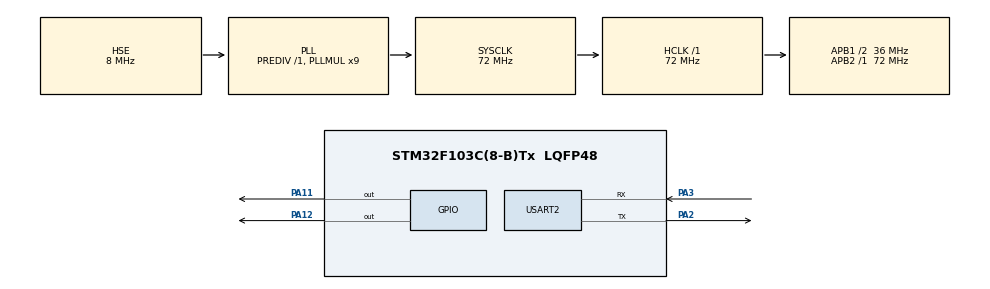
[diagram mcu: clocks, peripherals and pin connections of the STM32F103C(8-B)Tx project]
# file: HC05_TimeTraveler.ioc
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Mcu.Family=STM32F1
Mcu.Name=STM32F103C(8-B)Tx
Mcu.Package=LQFP48
NVIC.PriorityGroup=NVIC_PRIORITYGROUP_4
PA11.Signal=GPIO_Output
PA12.Signal=GPIO_Output
PA2.Mode=Asynchronous
PA2.Signal=USART2_TX
PA3.Mode=Asynchronous
PA3.Signal=USART2_RX
PD0-OSC_IN.Mode=HSE-External-Oscillator
PD0-OSC_IN.Signal=RCC_OSC_IN
PD1-OSC_OUT.Mode=HSE-External-Oscillator
PD1-OSC_OUT.Signal=RCC_OSC_OUT
ProjectManager.HeapSize=0x200
ProjectManager.StackSize=0x400
ProjectManager.TargetToolchain=STM32CubeIDE
RCC.AHBFreq_Value=72000000
RCC.APB1CLKDivider=RCC_HCLK_DIV2
RCC.APB1Freq_Value=36000000
RCC.APB1TimFreq_Value=72000000
RCC.APB2Freq_Value=72000000
RCC.APB2TimFreq_Value=72000000
RCC.HCLKFreq_Value=72000000
RCC.PLLMUL=RCC_PLL_MUL9
RCC.PLLSourceVirtual=RCC_PLLSOURCE_HSE
RCC.SYSCLKFreq_VALUE=72000000
RCC.SYSCLKSource=RCC_SYSCLKSOURCE_PLLCLK
RCC.USBFreq_Value=72000000
RTC.Date=14
RTC.Month=RTC_MONTH_NOVEMBER
RTC.Year=22
USART2.VirtualMode=VM_ASYNC
VP_RTC_VS_RTC_Activate.Mode=RTC_Enabled
VP_RTC_VS_RTC_Calendar.Mode=RTC_Calendar
board=custom

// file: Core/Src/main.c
/* USER CODE BEGIN Header */
/**
  ******************************************************************************
  * @file           : main.c
  * @brief          : Main program body
  ******************************************************************************
  * @attention
  *
  * Copyright (c) 2022 STMicroelectronics.
  * All rights reserved.
  *
  * This software is licensed under terms that can be found in the LICENSE file
  * in the root directory of this software component.
  * If no LICENSE file comes with this software, it is provided AS-IS.
  *
  ******************************************************************************
  */
/* USER CODE END Header */
#include "main.h"
#include <string.h>

RTC_HandleTypeDef hrtc;

UART_HandleTypeDef huart2;

void SystemClock_Config(void);
static void MX_GPIO_Init(void);
static void MX_RTC_Init(void);
static void MX_USART2_UART_Init(void);
void get_time(void);

int main(void)
{

  /* MCU Configuration--------------------------------------------------------*/

  /* Reset of all peripherals, Initializes the Flash interface and the Systick. */
  HAL_Init();

  /* Configure the system clock */
  SystemClock_Config();

  /* Initialize all configured peripherals */
  MX_GPIO_Init();
  MX_RTC_Init();//hay que ponerlo afuera del main ?NO.
  MX_USART2_UART_Init();

  /* Infinite loop */
  /* USER CODE BEGIN WHILE */
  char data_in[1];
  char msg0[]="\nHC-05 Bluetooth with STM32\n";
  char msg1[]="\nHola, la temperatura es: 27°C\n";
  char msg2[]="\nAT-COMMANDS\n";
  int32_t before = RTC_BKP_DR1;
  int32_t after = 0;
  int counterA=0;
  int counterB=0;
  char tramaA[60];
  char tramaB[60];
   //serapp
  HAL_UART_Transmit(&huart2, (uint8_t*) msg0, strlen(msg0), HAL_MAX_DELAY);
  while (1)
  {
     /* USER CODE END WHILE */
 	  HAL_UART_Receive(&huart2, (uint8_t*)data_in, 1, HAL_MAX_DELAY);
 	  //hacerlo pero con interrupts cosa que el counter
	  //cuente bien y no espere a recibir algo para actuar
 	  if(RTC_BKP_DR1 == before){
 		  counterA++;
 	  }else{
 		  counterB++;
 	  }
 	  before=RTC_BKP_DR1;

 	  if(data_in[0]=='1'){//hora
 		  HAL_GPIO_WritePin(GPIOA, GPIO_PIN_11, GPIO_PIN_RESET);
 		  //HAL_UART_Transmit(&huart2, (uint8_t*) msg2, strlen(msg2), HAL_MAX_DELAY);
 		  get_time();
 	  } else if (data_in[0]=='2'){//temperatura
 		  HAL_GPIO_WritePin(GPIOA, GPIO_PIN_11, GPIO_PIN_SET);
 		  sprintf(tramaA, "%hu A\n", counterA);
 		  sprintf(tramaB, "%hu B\n", counterB);
 		  strcat(tramaA,tramaB);
 		  strcat(msg1,tramaA);
 		  HAL_UART_Transmit(&huart2, (uint8_t*) msg1, strlen(msg1), HAL_MAX_DELAY);
 	  }
 	  else if (data_in[0]=='3') {//at
 		 HAL_UART_Transmit(&huart2, (uint8_t*) msg2, strlen(msg2), HAL_MAX_DELAY);
 	  }
   }
}

void SystemClock_Config(void)
{
  RCC_OscInitTypeDef RCC_OscInitStruct = {0};
  RCC_ClkInitTypeDef RCC_ClkInitStruct = {0};
  RCC_PeriphCLKInitTypeDef PeriphClkInit = {0};

  /** Initializes the RCC Oscillators according to the specified parameters
  * in the RCC_OscInitTypeDef structure.
  */
  RCC_OscInitStruct.OscillatorType = RCC_OSCILLATORTYPE_LSI|RCC_OSCILLATORTYPE_HSE;
  RCC_OscInitStruct.HSEState = RCC_HSE_ON;
  RCC_OscInitStruct.HSEPredivValue = RCC_HSE_PREDIV_DIV1;
  RCC_OscInitStruct.HSIState = RCC_HSI_ON;
  RCC_OscInitStruct.LSIState = RCC_LSI_ON;
  RCC_OscInitStruct.PLL.PLLState = RCC_PLL_ON;
  RCC_OscInitStruct.PLL.PLLSource = RCC_PLLSOURCE_HSE;
  RCC_OscInitStruct.PLL.PLLMUL = RCC_PLL_MUL9;
  if (HAL_RCC_OscConfig(&RCC_OscInitStruct) != HAL_OK)
  {
    Error_Handler();
  }

  /** Initializes the CPU, AHB and APB buses clocks
  */
  RCC_ClkInitStruct.ClockType = RCC_CLOCKTYPE_HCLK|RCC_CLOCKTYPE_SYSCLK
                              |RCC_CLOCKTYPE_PCLK1|RCC_CLOCKTYPE_PCLK2;
  RCC_ClkInitStruct.SYSCLKSource = RCC_SYSCLKSOURCE_PLLCLK;
  RCC_ClkInitStruct.AHBCLKDivider = RCC_SYSCLK_DIV1;
  RCC_ClkInitStruct.APB1CLKDivider = RCC_HCLK_DIV2;
  RCC_ClkInitStruct.APB2CLKDivider = RCC_HCLK_DIV1;

  if (HAL_RCC_ClockConfig(&RCC_ClkInitStruct, FLASH_LATENCY_2) != HAL_OK)
  {
    Error_Handler();
  }
  PeriphClkInit.PeriphClockSelection = RCC_PERIPHCLK_RTC;
  PeriphClkInit.RTCClockSelection = RCC_RTCCLKSOURCE_LSI;
  if (HAL_RCCEx_PeriphCLKConfig(&PeriphClkInit) != HAL_OK)
  {
    Error_Handler();
  }
}

static void MX_RTC_Init(void) //si la uso esta setea el time y un par de cosas más
{

  RTC_TimeTypeDef sTime = {0};
  RTC_DateTypeDef DateToUpdate = {0};

  /** Initialize RTC Only
  */
  hrtc.Instance = RTC;
  hrtc.Init.AsynchPrediv = RTC_AUTO_1_SECOND;
  hrtc.Init.OutPut = RTC_OUTPUTSOURCE_ALARM;
  if (HAL_RTC_Init(&hrtc) != HAL_OK)
  {
    Error_Handler();
  }

  /* USER CODE BEGIN Check_RTC_BKUP */ //no se si va así, si va así
  if(HAL_RTCEx_BKUPRead(&hrtc, RTC_BKP_DR1) == 0x32F2) {
	  //Time is OK. Set Alarms later.
	  //printf("RTC backup available\n");
	  	return;
  }
  //hacer un contador en un registro de back up que se incremente
  //cada vez que pase un segundo de tiempo del otro registro donde se guarda
  //la hora. Esto para saber cuanto tarda en guardar.
  /* USER CODE END Check_RTC_BKUP */

  /** Initialize RTC and set the Time and Date
  */
  sTime.Hours = 0x0;
  sTime.Minutes = 0x0;
  sTime.Seconds = 0x0;

  if (HAL_RTC_SetTime(&hrtc, &sTime, RTC_FORMAT_BCD) != HAL_OK)
  {
    Error_Handler();
  }
  DateToUpdate.WeekDay = RTC_WEEKDAY_MONDAY;
  DateToUpdate.Month = RTC_MONTH_NOVEMBER;
  DateToUpdate.Date = 0x14;
  DateToUpdate.Year = 0x22;

  if (HAL_RTC_SetDate(&hrtc, &DateToUpdate, RTC_FORMAT_BCD) != HAL_OK)
  {
    Error_Handler();
  }
  /* USER CODE BEGIN RTC_Init 2 */
  HAL_RTCEx_BKUPWrite(&hrtc, RTC_BKP_DR1, 0x32F2);
  /* USER CODE END RTC_Init 2 */

}

static void MX_USART2_UART_Init(void)
{

  huart2.Instance = USART2;
  //huart2.Init.BaudRate = 38400;
  huart2.Init.BaudRate = 9600;
  huart2.Init.WordLength = UART_WORDLENGTH_8B;
  huart2.Init.StopBits = UART_STOPBITS_1;
  huart2.Init.Parity = UART_PARITY_NONE;
  huart2.Init.Mode = UART_MODE_TX_RX;
  huart2.Init.HwFlowCtl = UART_HWCONTROL_NONE;
  huart2.Init.OverSampling = UART_OVERSAMPLING_16;
  if (HAL_UART_Init(&huart2) != HAL_OK)
  {
    Error_Handler();
  }

}

void set_time (void)//no la uso
{
  RTC_TimeTypeDef sTime;
  RTC_DateTypeDef sDate;
  sTime.Hours = 0x10; // set hours
  sTime.Minutes = 0x20; // set minutes
  sTime.Seconds = 0x30; // set seconds
  //sTime.DayLightSaving = RTC_DAYLIGHTSAVING_NONE;
  //sTime.StoreOperation = RTC_STOREOPERATION_RESET;
  if (HAL_RTC_SetTime(&hrtc, &sTime, RTC_FORMAT_BCD) != HAL_OK)
  {
    _Error_Handler(__FILE__, __LINE__);
  }
  sDate.WeekDay = RTC_WEEKDAY_THURSDAY; // day
  sDate.Month = RTC_MONTH_AUGUST; // month
  sDate.Date = 0x9; // date
  sDate.Year = 0x18; // year
  if (HAL_RTC_SetDate(&hrtc, &sDate, RTC_FORMAT_BCD) != HAL_OK)
  {
    _Error_Handler(__FILE__, __LINE__);
  }
  HAL_RTCEx_BKUPWrite(&hrtc, RTC_BKP_DR1, 0x32F2); // backup register
}

void get_time(void)
{
 char timer[9];
 char date[12];
 RTC_DateTypeDef gDate;
 RTC_TimeTypeDef gTime;
/* Get the RTC current Time */
 HAL_RTC_GetTime(&hrtc, &gTime, RTC_FORMAT_BIN);
/* Get the RTC current Date */
 HAL_RTC_GetDate(&hrtc, &gDate, RTC_FORMAT_BIN);
/* Display time Format: hh:mm:ss */
 sprintf(timer,"%02d:%02d:%02d\n",gTime.Hours, gTime.Minutes, gTime.Seconds);
 HAL_UART_Transmit(&huart2, (uint8_t*) timer, strlen(timer), HAL_MAX_DELAY);
/* Display date Format: dd-mm-yy */
 sprintf(date,"%02d-%02d-%2d\n",gDate.Date, gDate.Month, 2000 + gDate.Year);
 HAL_UART_Transmit(&huart2, (uint8_t*) date, strlen(date), HAL_MAX_DELAY);
}

static void MX_GPIO_Init(void)
{
  GPIO_InitTypeDef GPIO_InitStruct = {0};

  /* GPIO Ports Clock Enable */
  __HAL_RCC_GPIOD_CLK_ENABLE();
  __HAL_RCC_GPIOA_CLK_ENABLE();

  /*Configure GPIO pin Output Level */
  HAL_GPIO_WritePin(GPIOA, GPIO_PIN_11|GPIO_PIN_12, GPIO_PIN_RESET);

  /*Configure GPIO pins : PA11 PA12 */
  GPIO_InitStruct.Pin = GPIO_PIN_11|GPIO_PIN_12;
  GPIO_InitStruct.Mode = GPIO_MODE_OUTPUT_PP;
  GPIO_InitStruct.Pull = GPIO_NOPULL;
  GPIO_InitStruct.Speed = GPIO_SPEED_FREQ_LOW;
  HAL_GPIO_Init(GPIOA, &GPIO_InitStruct);

}

void Error_Handler(void)
{
  __disable_irq();
  while (1)
  {
  }
}
